# S6E2D3 register map
File version: 1.1
CPU: CM4 r0p1, little endian, MPU, FPU, 4 interrupt priority bits
Registers are 32-bit, read-write, reset 0x0 unless marked. A register's access mark holds for its fields unless they carry their own. Offsets are from the block's base; [hi:lo] are bit positions; {n}, {i} and the like mark numbered series; 'fields as' and 'values as' point back to an identical list.

## FLASH_IF — Flash Memory
Base 0x40000000
0x00 FASZR reset 0x2 — Flash Access Size Register
  [1:0] ASZ — Access Size
0x04 FRWTR reset 0x3 — Flash Read Wait Register
  [1:0] RWT — Read Wait Cycle
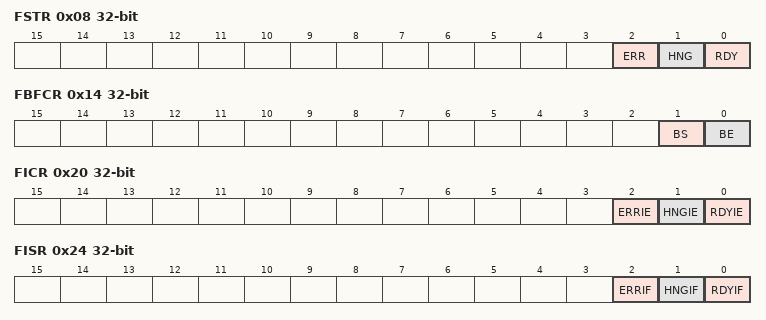
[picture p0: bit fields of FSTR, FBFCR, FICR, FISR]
0x08 FSTR — Flash Status Register
  [2] ERR — Flash ECC Error
  [1] HNG ro — Flash Hang
  [0] RDY ro — Flash Rdy
0x10 FSYNDN — Flash Sync Down Register
  [2:0] SD — Sync Down
0x14 FBFCR — Flash Buffer Control Register
  [1] BS ro — Buffer Status
  [0] BE — Buffer Enable
0x20 FICR — Flash Interrupt Control Register
  [2] ERRIE — Flash ECC Error Interrupt Enable
  [1] HNGIE — Flash HANG Interrupt Enable
  [0] RDYIE — Flash RDY Interrupt Enable
0x24 FISR ro — Flash Interrupt Status Register
  [2] ERRIF — Flash ECC Error Interrupt Flag
  [1] HNGIF — Flash HANG Interrupt Flag
  [0] RDYIF — Flash RDY Interrupt Flag
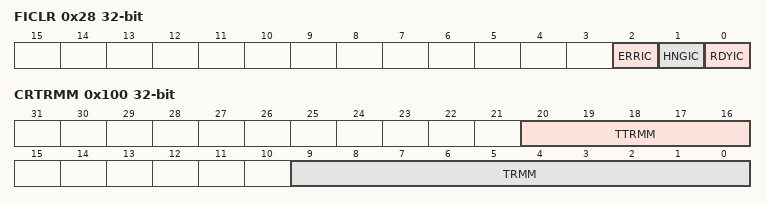
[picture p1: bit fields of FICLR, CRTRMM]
0x28 FICLR — Flash Interrupt Clear Register
  [2] ERRIC — Flash ECC Error Interrupt Clear
  [1] HNGIC — Flash HANG Interrupt Clear
  [0] RDYIC — Flash RDY Interrupt Clear
0x100 CRTRMM ro — CR Trimming Data Mirror Register
  [20:16] TTRMM — Temperature CR Trimming Data Mirror
  [9:0] TRMM — CR Trimming Data Mirror
{0x10C+4i} FGPDM{i} ro (i=1..4) — Flash General Purpose Data Mirror Register{i}
  [31:0] GPD{i} — General Purpose Data{i}

## UNIQUE_ID
Base 0x40000200
0x00 UIDR0 ro — Unique ID Register 0
  [31:4] UID — Unique ID 27 through 0
0x04 UIDR1 ro — Unique ID Register 1
  [12:0] UID — Unique ID 40 through 28

## ECC_CAPTURE — ECC Capture Address
Base 0x40000300
0x00 FERRAD ro — Flash ECC Error Address Capture Register
  [22:0] ERRAD — Flash ECC Error Address Capture

## HWWDT — Hardware Watchdog Timer
Base 0x40011000
0x00 WDG_LDR reset 0xFFFF — Hardware Watchdog Timer Load Register
0x04 WDG_VLR ro — Hardware Watchdog Timer Value Register
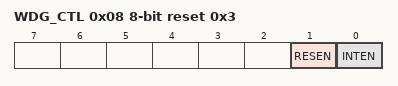
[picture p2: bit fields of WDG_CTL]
0x08 WDG_CTL 8-bit reset 0x3 — Hardware Watchdog Timer Control Register
  [1] RESEN — Hardware watchdog reset enable bit
  [0] INTEN — Hardware watchdog interrupt and counter enable bit
0x0C WDG_ICL 8-bit reset 0xFF (reset mask 0x0) — Hardware Watchdog Timer Clear Register
0x10 WDG_RIS 8-bit ro reset 0xFF (reset mask 0x0) — Hardware Watchdog Timer Interrupt Status Register
  [0] RIS — Hardware watchdog interrupt status bit
0xC00 WDG_LCK reset 0x1 — Hardware Watchdog Timer Lock Register

## SWWDT — Software Watchdog Timer
Base 0x40012000
0x00 WDOGLOAD reset 0xFFFFFFFF — Software Watchdog Timer Load Register
0x04 WDOGVALUE ro reset 0xFFFFFFFF — Software Watchdog Timer Value Register
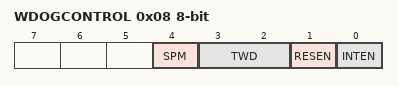
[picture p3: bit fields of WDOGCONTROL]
0x08 WDOGCONTROL 8-bit — Software Watchdog Timer Control Register
  [4] SPM — Software Watchdog window watchdog mode enable bit
  [3:2] TWD — Timing window setting bit of the software watchdog
  [1] RESEN — Reset enable bit of the software watchdog
  [0] INTEN — Interrupt and counter enable bit of the software watchdog
0x0C WDOGINTCLR reset 0xFFFFFFFF — Software Watchdog Timer Clear Register
0x10 WDOGRIS 8-bit ro — Software Watchdog Timer Interrupt Status Register
  [0] RIS — Software watchdog interrupt status bit
0x18 WDOGSPMC 8-bit — Software Watchdog Timer Window Watchdog Mode Control Register
  [0] TGR ro — Software watchdog trigger type bit
0xC00 WDOGLOCK — Software Watchdog Timer Lock Register

## DTIM — Dual Timer
Base 0x40015000
0x00 TIMER1LOAD (DualTimer1 view) — Load Register
0x04 TIMER1VALUE ro reset 0xFFFFFFFF — Value Register
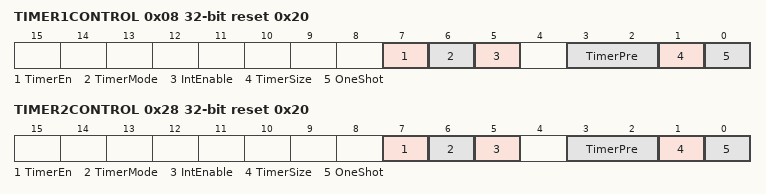
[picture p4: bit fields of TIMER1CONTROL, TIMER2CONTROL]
0x08 TIMER1CONTROL reset 0x20 — Control Register
  [7] TimerEn — Enable bit
  [6] TimerMode — Mode bit
  [5] IntEnable — Interrupt enable bit
  [3:2] TimerPre — Prescale bits
  [1] TimerSize — Counter size bit
  [0] OneShot — One-shot mode bit
0x0C TIMER1INTCLR wo reset not defined — Interrupt Clear Register
0x10 TIMER1RIS ro — Interrupt Status Register
  [0] TIMER1RIS — Interrupt Status Register bit
0x14 TIMER1MIS ro — Masked Interrupt Status Register
  [0] TIMER1MIS — Masked Interrupt Status bit
0x18 TIMER1BGLOAD — Background Load Register
0x20 TIMER2LOAD — Load Register
0x24 TIMER2VALUE ro reset 0xFFFFFFFF — Value Register
0x28 TIMER2CONTROL reset 0x20 — Control Register
  fields as TIMER1CONTROL
0x2C TIMER2INTCLR wo reset not defined — Interrupt Clear Register
0x30 TIMER2RIS ro — Interrupt Status Register
  [0] TIMER1RIS — Interrupt Status Register bit
0x34 TIMER2MIS ro — Masked Interrupt Status Register
  [0] TIMER1MIS — Masked Interrupt Status bit
0x38 TIMER2BGLOAD — Background Load Register
